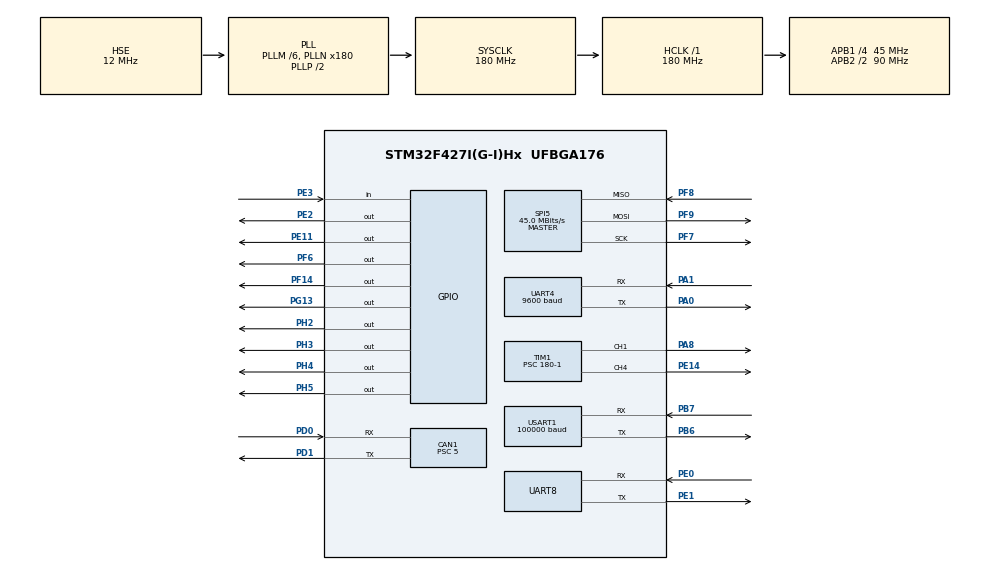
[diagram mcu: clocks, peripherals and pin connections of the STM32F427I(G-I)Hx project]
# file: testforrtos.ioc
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CAN1.BS1=CAN_BS1_3TQ
CAN1.BS2=CAN_BS2_5TQ
CAN1.CalculateTimeQuantum=111.11111111111111
CAN1.Prescaler=5
CAN1.SJW=CAN_SJW_1TQ
CAN1.TTCM=ENABLE
CAN1.TXFP=ENABLE
Dma.Request0=USART1_RX
Dma.Request1=UART8_RX
Dma.UART8_RX.1.Direction=DMA_PERIPH_TO_MEMORY
Dma.UART8_RX.1.FIFOMode=DMA_FIFOMODE_DISABLE
Dma.UART8_RX.1.Instance=DMA1_Stream6
Dma.UART8_RX.1.MemDataAlignment=DMA_MDATAALIGN_BYTE
Dma.UART8_RX.1.MemInc=DMA_MINC_ENABLE
Dma.UART8_RX.1.Mode=DMA_CIRCULAR
Dma.UART8_RX.1.PeriphDataAlignment=DMA_PDATAALIGN_BYTE
Dma.UART8_RX.1.PeriphInc=DMA_PINC_DISABLE
Dma.UART8_RX.1.Priority=DMA_PRIORITY_LOW
Dma.USART1_RX.0.Direction=DMA_PERIPH_TO_MEMORY
Dma.USART1_RX.0.FIFOMode=DMA_FIFOMODE_DISABLE
Dma.USART1_RX.0.Instance=DMA2_Stream2
Dma.USART1_RX.0.MemDataAlignment=DMA_MDATAALIGN_BYTE
Dma.USART1_RX.0.MemInc=DMA_MINC_ENABLE
Dma.USART1_RX.0.Mode=DMA_CIRCULAR
Dma.USART1_RX.0.PeriphDataAlignment=DMA_PDATAALIGN_BYTE
Dma.USART1_RX.0.PeriphInc=DMA_PINC_DISABLE
Dma.USART1_RX.0.Priority=DMA_PRIORITY_VERY_HIGH
FREERTOS.INCLUDE_vTaskDelayUntil=1
FREERTOS.Tasks01=defaultTask,0,128,StartDefaultTask,Default,NULL,Dynamic,NULL,NULL;LEDFlashTask,-2,128,LEDFlash_Task,As external,NULL,Dynamic,NULL,NULL;detecttask,-2,128,detect_task,As external,NULL,Dynamic,NULL,NULL;Sensortask,0,128,Sensor_task,As external,NULL,Dynamic,NULL,NULL;gimbaltask,-2,128,gimbal_task,As external,NULL,Dynamic,NULL,NULL;chassistask,-2,128,chassis_task,As external,NULL,Dynamic,NULL,NULL;autoaimtask,-2,128,auto_aim_task,As external,NULL,Dynamic,NULL,NULL;Shoottask,0,128,shoot_task,As external,NULL,Dynamic,NULL,NULL
FREERTOS.configLIBRARY_MAX_SYSCALL_INTERRUPT_PRIORITY=5
FREERTOS.configMAX_PRIORITIES=10
Mcu.Family=STM32F4
Mcu.Name=STM32F427I(G-I)Hx
Mcu.Package=UFBGA176
NVIC.CAN1_RX0_IRQn=true\:3\:0\:true\:false\:true\:false\:true\:true
NVIC.CAN1_TX_IRQn=true\:5\:0\:true\:false\:true\:true\:true\:true
NVIC.DMA1_Stream6_IRQn=true\:5\:0\:true\:false\:true\:true\:false\:true
NVIC.DMA2_Stream2_IRQn=true\:5\:0\:true\:false\:true\:true\:false\:true
NVIC.PriorityGroup=NVIC_PRIORITYGROUP_4
NVIC.TIM5_IRQn=true\:0\:0\:false\:false\:true\:false\:false\:true
NVIC.TimeBase=TIM5_IRQn
NVIC.TimeBaseIP=TIM5
PA0/WKUP.Mode=Asynchronous
PA0/WKUP.Signal=UART4_TX
PA1.Mode=Asynchronous
PA1.Signal=UART4_RX
PA8.Signal=S_TIM1_CH1
PB6.Mode=Multiprocessor_communication
PB6.Signal=USART1_TX
PB7.Mode=Multiprocessor_communication
PB7.Signal=USART1_RX
PD0.Mode=Master
PD0.Signal=CAN1_RX
PD1.Mode=Master
PD1.Signal=CAN1_TX
PE0.Mode=Asynchronous
PE0.Signal=UART8_RX
PE1.Mode=Asynchronous
PE1.Signal=UART8_TX
PE11.Signal=GPIO_Output
PE14.Signal=S_TIM1_CH4
PE2.Signal=GPIO_Output
PE3.Signal=GPIO_Input
PF14.Signal=GPIO_Output
PF6.GPIO_ModeDefaultOutputPP=GPIO_MODE_OUTPUT_PP
PF6.GPIO_PuPd=GPIO_NOPULL
PF6.GPIO_Speed=GPIO_SPEED_FREQ_HIGH
PF6.Signal=GPIO_Output
PF7.Mode=Full_Duplex_Master
PF7.Signal=SPI5_SCK
PF8.Mode=Full_Duplex_Master
PF8.Signal=SPI5_MISO
PF9.Mode=Full_Duplex_Master
PF9.Signal=SPI5_MOSI
PG13.Signal=GPIO_Output
PH0/OSC_IN.Mode=HSE-External-Oscillator
PH0/OSC_IN.Signal=RCC_OSC_IN
PH1/OSC_OUT.Mode=HSE-External-Oscillator
PH1/OSC_OUT.Signal=RCC_OSC_OUT
PH2.Signal=GPIO_Output
PH3.Signal=GPIO_Output
PH4.Signal=GPIO_Output
PH5.Signal=GPIO_Output
ProjectManager.HeapSize=0x200
ProjectManager.StackSize=0x400
ProjectManager.TargetToolchain=MDK-ARM V5
RCC.48MHZClocksFreq_Value=90000000
RCC.AHBFreq_Value=180000000
RCC.APB1CLKDivider=RCC_HCLK_DIV4
RCC.APB1Freq_Value=45000000
RCC.APB1TimFreq_Value=90000000
RCC.APB2CLKDivider=RCC_HCLK_DIV2
RCC.APB2Freq_Value=90000000
RCC.APB2TimFreq_Value=180000000
RCC.CortexFreq_Value=180000000
RCC.HCLKFreq_Value=180000000
RCC.HSE_VALUE=12000000
RCC.HSI_VALUE=16000000
RCC.LSE_VALUE=32768
RCC.PLLM=6
RCC.PLLN=180
RCC.PLLSourceVirtual=RCC_PLLSOURCE_HSE
RCC.SYSCLKFreq_VALUE=180000000
RCC.SYSCLKSource=RCC_SYSCLKSOURCE_PLLCLK
RCC.VCOOutputFreq_Value=360000000
SH.S_TIM1_CH1.0=TIM1_CH1,Output Compare1 CH1
SH.S_TIM1_CH4.0=TIM1_CH4,Output Compare4 CH4
SPI5.CalculateBaudRate=45.0 MBits/s
SPI5.Direction=SPI_DIRECTION_2LINES
SPI5.Mode=SPI_MODE_MASTER
SPI5.VirtualType=VM_MASTER
TIM1.Channel-Output\ Compare1\ CH1=TIM_CHANNEL_1
TIM1.Channel-Output\ Compare4\ CH4=TIM_CHANNEL_4
TIM1.Period=2500-1
TIM1.Prescaler=180-1
UART4.BaudRate=9600
UART4.VirtualMode=Asynchronous
UART8.VirtualMode=Asynchronous
USART1.BaudRate=100000
USART1.VirtualMode=VM_ASYNC
VP_FREERTOS_VS_CMSIS_V1.Mode=CMSIS_V1
VP_SYS_VS_tim5.Mode=TIM5
board=custom

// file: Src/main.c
/* USER CODE BEGIN Header */
/**
  ******************************************************************************
  * @file           : main.c
  * @brief          : Main program body
  ******************************************************************************
  * @attention
  *
  * <h2><center>&copy; Copyright (c) 2019 STMicroelectronics.
  * All rights reserved.</center></h2>
  *
  * This software component is licensed by ST under BSD 3-Clause license,
  * the "License"; You may not use this file except in compliance with the
  * License. You may obtain a copy of the License at:
  *                        opensource.org/licenses/BSD-3-Clause
  *
  ******************************************************************************
  */
/* USER CODE END Header */

#include "main.h"
#include "cmsis_os.h"
#include "can.h"
#include "dma.h"
#include "spi.h"
#include "tim.h"
#include "usart.h"
#include "gpio.h"

/* USER CODE BEGIN Includes */
#include "can_receive.h"
#include "remote.h"
#include "ist8310.h"
#include "auto_aim_task.h"

/* USER CODE END Includes */

void SystemClock_Config(void);
void MX_FREERTOS_Init(void);

int main(void)
{

  /* MCU Configuration--------------------------------------------------------*/

  /* Reset of all peripherals, Initializes the Flash interface and the Systick. */
  HAL_Init();

  /* Configure the system clock */
  SystemClock_Config();

  /* Initialize all configured peripherals */
  MX_GPIO_Init();
  MX_DMA_Init();
  MX_SPI5_Init();
  MX_USART1_UART_Init();
  MX_CAN1_Init();
  MX_UART4_Init();
  MX_TIM1_Init();
  MX_UART8_Init();
  /* USER CODE BEGIN 2 */
  CAN1_Init();
  HAL_UART_Receive_DMA(&huart1,teledata_rx,sizeof(teledata_rx));

  /* USER CODE END 2 */

  /* Call init function for freertos objects (in freertos.c) */
  MX_FREERTOS_Init();

  /* Start scheduler */
  osKernelStart();

  /* We should never get here as control is now taken by the scheduler */

  /* Infinite loop */
  while (1)
  {

  }
}

void SystemClock_Config(void)
{
  RCC_OscInitTypeDef RCC_OscInitStruct = {0};
  RCC_ClkInitTypeDef RCC_ClkInitStruct = {0};

  /** Configure the main internal regulator output voltage
  */
  __HAL_RCC_PWR_CLK_ENABLE();
  __HAL_PWR_VOLTAGESCALING_CONFIG(PWR_REGULATOR_VOLTAGE_SCALE1);
  /** Initializes the CPU, AHB and APB busses clocks
  */
  RCC_OscInitStruct.OscillatorType = RCC_OSCILLATORTYPE_HSE;
  RCC_OscInitStruct.HSEState = RCC_HSE_ON;
  RCC_OscInitStruct.PLL.PLLState = RCC_PLL_ON;
  RCC_OscInitStruct.PLL.PLLSource = RCC_PLLSOURCE_HSE;
  RCC_OscInitStruct.PLL.PLLM = 6;
  RCC_OscInitStruct.PLL.PLLN = 180;
  RCC_OscInitStruct.PLL.PLLP = RCC_PLLP_DIV2;
  RCC_OscInitStruct.PLL.PLLQ = 4;
  if (HAL_RCC_OscConfig(&RCC_OscInitStruct) != HAL_OK)
  {
    Error_Handler();
  }
  /** Activate the Over-Drive mode
  */
  if (HAL_PWREx_EnableOverDrive() != HAL_OK)
  {
    Error_Handler();
  }
  /** Initializes the CPU, AHB and APB busses clocks
  */
  RCC_ClkInitStruct.ClockType = RCC_CLOCKTYPE_HCLK|RCC_CLOCKTYPE_SYSCLK
                              |RCC_CLOCKTYPE_PCLK1|RCC_CLOCKTYPE_PCLK2;
  RCC_ClkInitStruct.SYSCLKSource = RCC_SYSCLKSOURCE_PLLCLK;
  RCC_ClkInitStruct.AHBCLKDivider = RCC_SYSCLK_DIV1;
  RCC_ClkInitStruct.APB1CLKDivider = RCC_HCLK_DIV4;
  RCC_ClkInitStruct.APB2CLKDivider = RCC_HCLK_DIV2;

  if (HAL_RCC_ClockConfig(&RCC_ClkInitStruct, FLASH_LATENCY_5) != HAL_OK)
  {
    Error_Handler();
  }
}

void HAL_TIM_PeriodElapsedCallback(TIM_HandleTypeDef *htim)
{
  if (htim->Instance == TIM5) {
    HAL_IncTick();
  }
}

void Error_Handler(void)
{
}

/************************ (C) COPYRIGHT STMicroelectronics *****END OF FILE****/

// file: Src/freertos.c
/* USER CODE BEGIN Header */
/**
  ******************************************************************************
  * File Name          : freertos.c
  * Description        : Code for freertos applications
  ******************************************************************************
  * @attention
  *
  * <h2><center>&copy; Copyright (c) 2019 STMicroelectronics.
  * All rights reserved.</center></h2>
  *
  * This software component is licensed by ST under Ultimate Liberty license
  * SLA0044, the "License"; You may not use this file except in compliance with
  * the License. You may obtain a copy of the License at:
  *                             www.st.com/SLA0044
  *
  ******************************************************************************
  */
/* USER CODE END Header */

#include "FreeRTOS.h"
#include "task.h"
#include "main.h"
#include "cmsis_os.h"

osThreadId defaultTaskHandle;
osThreadId LEDFlashTaskHandle;
osThreadId detecttaskHandle;
osThreadId SensortaskHandle;
osThreadId gimbaltaskHandle;
osThreadId chassistaskHandle;
osThreadId autoaimtaskHandle;
osThreadId ShoottaskHandle;

void StartDefaultTask(void const * argument);
extern void LEDFlash_Task(void const * argument);
extern void detect_task(void const * argument);
extern void Sensor_task(void const * argument);
extern void gimbal_task(void const * argument);
extern void chassis_task(void const * argument);
extern void auto_aim_task(void const * argument);
extern void shoot_task(void const * argument);

void MX_FREERTOS_Init(void); /* (MISRA C 2004 rule 8.1) */

/* GetIdleTaskMemory prototype (linked to static allocation support) */
void vApplicationGetIdleTaskMemory( StaticTask_t **ppxIdleTaskTCBBuffer, StackType_t **ppxIdleTaskStackBuffer, uint32_t *pulIdleTaskStackSize );

/* USER CODE BEGIN GET_IDLE_TASK_MEMORY */
static StaticTask_t xIdleTaskTCBBuffer;
static StackType_t xIdleStack[configMINIMAL_STACK_SIZE];

void vApplicationGetIdleTaskMemory( StaticTask_t **ppxIdleTaskTCBBuffer, StackType_t **ppxIdleTaskStackBuffer, uint32_t *pulIdleTaskStackSize )
{
  *ppxIdleTaskTCBBuffer = &xIdleTaskTCBBuffer;
  *ppxIdleTaskStackBuffer = &xIdleStack[0];
  *pulIdleTaskStackSize = configMINIMAL_STACK_SIZE;
  /* place for user code */
}
/* USER CODE END GET_IDLE_TASK_MEMORY */

void MX_FREERTOS_Init(void) {

  /* Create the thread(s) */
  /* definition and creation of defaultTask */
  osThreadDef(defaultTask, StartDefaultTask, osPriorityNormal, 0, 128);
  defaultTaskHandle = osThreadCreate(osThread(defaultTask), NULL);

  /* definition and creation of LEDFlashTask */
  osThreadDef(LEDFlashTask, LEDFlash_Task, osPriorityLow, 0, 128);
  LEDFlashTaskHandle = osThreadCreate(osThread(LEDFlashTask), NULL);

  /* definition and creation of detecttask */
  osThreadDef(detecttask, detect_task, osPriorityLow, 0, 128);
  detecttaskHandle = osThreadCreate(osThread(detecttask), NULL);

  /* definition and creation of Sensortask */
  osThreadDef(Sensortask, Sensor_task, osPriorityNormal, 0, 128);
  SensortaskHandle = osThreadCreate(osThread(Sensortask), NULL);

  /* definition and creation of gimbaltask */
  osThreadDef(gimbaltask, gimbal_task, osPriorityLow, 0, 128);
  gimbaltaskHandle = osThreadCreate(osThread(gimbaltask), NULL);

  /* definition and creation of chassistask */
  osThreadDef(chassistask, chassis_task, osPriorityLow, 0, 128);
  chassistaskHandle = osThreadCreate(osThread(chassistask), NULL);

  /* definition and creation of autoaimtask */
  osThreadDef(autoaimtask, auto_aim_task, osPriorityLow, 0, 128);
  autoaimtaskHandle = osThreadCreate(osThread(autoaimtask), NULL);

  /* definition and creation of Shoottask */
  osThreadDef(Shoottask, shoot_task, osPriorityNormal, 0, 128);
  ShoottaskHandle = osThreadCreate(osThread(Shoottask), NULL);

}

void StartDefaultTask(void const * argument)
{

  for(;;)
  {
    osDelay(1);
  }
}

/************************ (C) COPYRIGHT STMicroelectronics *****END OF FILE****/
